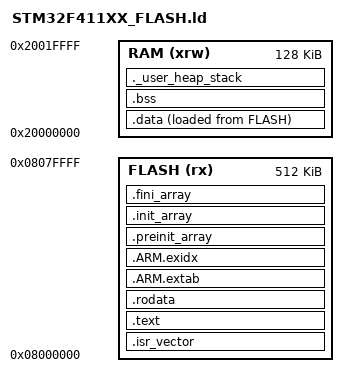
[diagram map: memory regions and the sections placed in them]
/* Entry Point */
ENTRY(Reset_Handler)

/* Memory layout */
MEMORY
{
  FLASH (rx)  : ORIGIN = 0x08000000, LENGTH = 512K
  RAM   (xrw) : ORIGIN = 0x20000000, LENGTH = 128K
}

/* End of RAM = initial MSP */
_estack = ORIGIN(RAM) + LENGTH(RAM);

/* Minimum heap/stack (used only for link-time check) */
_Min_Heap_Size  = 0x200;
_Min_Stack_Size = 0x400;

/* Sections */
SECTIONS
{
  /* Vector table */
  .isr_vector :
  {
    . = ALIGN(4);
    KEEP(*(.isr_vector))
    . = ALIGN(4);
  } > FLASH

  /* Code */
  .text :
  {
    . = ALIGN(4);
    *(.text)
    *(.text*)
    *(.glue_7)
    *(.glue_7t)
    *(.eh_frame)

    KEEP(*(.init))
    KEEP(*(.fini))

    . = ALIGN(4);
    _etext = .;
  } > FLASH

  /* Read-only data */
  .rodata :
  {
    . = ALIGN(4);
    *(.rodata)
    *(.rodata*)
    . = ALIGN(4);
  } > FLASH

  /* Exception tables */
  .ARM.extab :
  {
    . = ALIGN(4);
    *(.ARM.extab* .gnu.linkonce.armextab.*)
    . = ALIGN(4);
  } > FLASH

  .ARM.exidx :
  {
    . = ALIGN(4);
    __exidx_start = .;
    *(.ARM.exidx*)
    __exidx_end = .;
    . = ALIGN(4);
  } > FLASH

  /* Init arrays */
  .preinit_array :
  {
    . = ALIGN(4);
    PROVIDE(__preinit_array_start = .);
    KEEP(*(.preinit_array*))
    PROVIDE(__preinit_array_end = .);
    . = ALIGN(4);
  } > FLASH

  .init_array :
  {
    . = ALIGN(4);
    PROVIDE(__init_array_start = .);
    KEEP(*(SORT(.init_array.*)))
    KEEP(*(.init_array*))
    PROVIDE(__init_array_end = .);
    . = ALIGN(4);
  } > FLASH

  .fini_array :
  {
    . = ALIGN(4);
    PROVIDE(__fini_array_start = .);
    KEEP(*(SORT(.fini_array.*)))
    KEEP(*(.fini_array*))
    PROVIDE(__fini_array_end = .);
    . = ALIGN(4);
  } > FLASH

  /* Data copied from flash to RAM */
  _sidata = LOADADDR(.data);

  .data :
  {
    . = ALIGN(4);
    _sdata = .;
    *(.data)
    *(.data*)
    *(.RamFunc)
    *(.RamFunc*)
    . = ALIGN(4);
    _edata = .;
  } > RAM AT > FLASH

  /* Zero-initialized data */
  .bss (NOLOAD) :
  {
    . = ALIGN(4);
    _sbss = .;
    __bss_start__ = _sbss;

    *(.bss)
    *(.bss*)
    *(COMMON)

    . = ALIGN(4);
    _ebss = .;
    __bss_end__ = _ebss;
  } > RAM

  /* Heap + stack safety region */
  ._user_heap_stack (NOLOAD) :
  {
    . = ALIGN(8);
    PROVIDE(end = .);
    PROVIDE(_end = .);
    . = . + _Min_Heap_Size;
    . = . + _Min_Stack_Size;
    . = ALIGN(8);
  } > RAM

  /* Strip standard libraries */
  /DISCARD/ :
  {
    libc.a(*)
    libm.a(*)
    libgcc.a(*)
  }
}
